# GD32M53x register map
File version: 1.0
CPU: CM33 r2p1, little endian, MPU, FPU, DSP, 4 interrupt priority bits
Registers are 32-bit, read-write, reset 0x0 unless marked. A register's access mark holds for its fields unless they carry their own. Offsets are from the block's base; [hi:lo] are bit positions; {n}, {i} and the like mark numbered series.

## CFMU — Clock frequency measurement unit
Base 0x4000C800
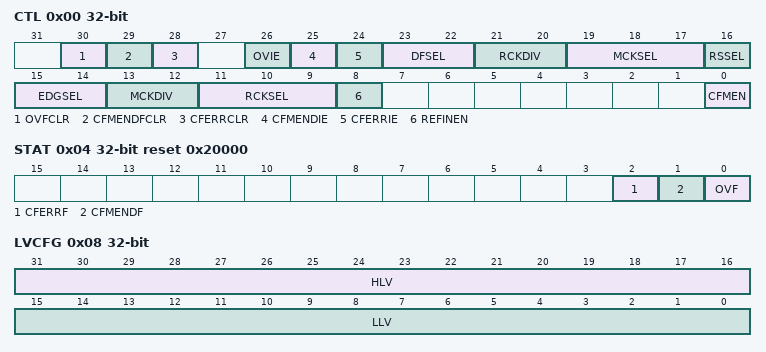
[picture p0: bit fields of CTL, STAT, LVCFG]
0x00 CTL — Control register
  [30] OVFCLR — Overflow flag clear
  [29] CFMENDFCLR — Clock frequency measurement end flag clear
  [28] CFERRCLR — Clock frequency error flag clear
  [26] OVIE — Overflow interrupt enable
  [25] CFMENDIE — Clock frequency measurement end interrupt enable
  [24] CFERRIE — Clock frequency error interrupt enable
  [23:22] DFSEL — Digital filter select
  [21:20] RCKDIV — Reference clock frequency divider
  [19:17] MCKSEL — Measurement clock select
  [16] RSSEL — Reference signal select
  [15:14] EDGSEL — Edge select
  [13:12] MCKDIV — Measurement clock frequency divider
  [11:9] RCKSEL — Reference clock select
  [8] REFINEN — CFMUREF pin input enable
  [0] CFMEN — Clock frequency measurement enable
0x04 STAT ro reset 0x20000 — Status register
  [2] CFERRF — Clock frequency error flag
  [1] CFMENDF — Clock frequency measurement end flag
  [0] OVF — Counter overflow flag
0x08 LVCFG — Limit value configuration register
  [31:16] HLV — Higher-limit value
  [15:0] LLV — Lower-limit value
0x0C CNT ro — Counter value register
  [15:0] CNT — Counter value

## CMP — Comparator
Base 0x40017C00
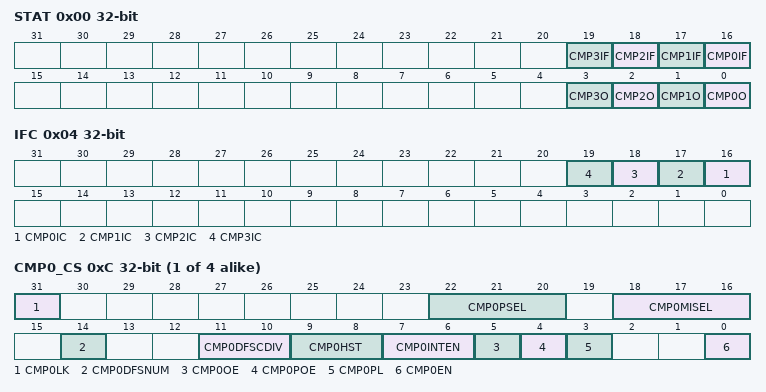
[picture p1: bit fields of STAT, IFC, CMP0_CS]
0x00 STAT ro — CMP status register
  [n+16] CMP{n}IF (n=0..3) — CMP{n} interrupt flag
  [n] CMP{n}O (n=0..3) — CMP{n} output state
0x04 IFC wo — CMP interrupt flag clear register
  [n+16] CMP{n}IC (n=0..3) — CMP{n} interrupt flag clear
{0xC+4i} CMP{i}_CS (i=0..3) — CMP{i} control and status register
  [31] CMP{i}LK — CMP{i} lock
  [22:20] CMP{i}PSEL — CMP{i}_IP input selection
  [18:16] CMP{i}MISEL — CMP{i}_IM internal input selection
  [14] CMP{i}DFSNUM — CMP{i} digital filter sampling number
  [11:10] CMP{i}DFSCDIV — CMP{i} digital filter sampling clock division
  [9:8] CMP{i}HST — CMP{i} hysteresis
  [7:6] CMP{i}INTEN — CMP{i} interrupt request enable
  [5] CMP{i}OE — CMP{i} Output Enable
  [4] CMP{i}POE — CMP{i} Pin Output Enable
  [3] CMP{i}PL — Polarity of CMP{i} output
  [0] CMP{i}EN — CMP{i} enable

## CPTIMER0
Base 0x40000000
Same registers: CPTIMER1 0x40000400
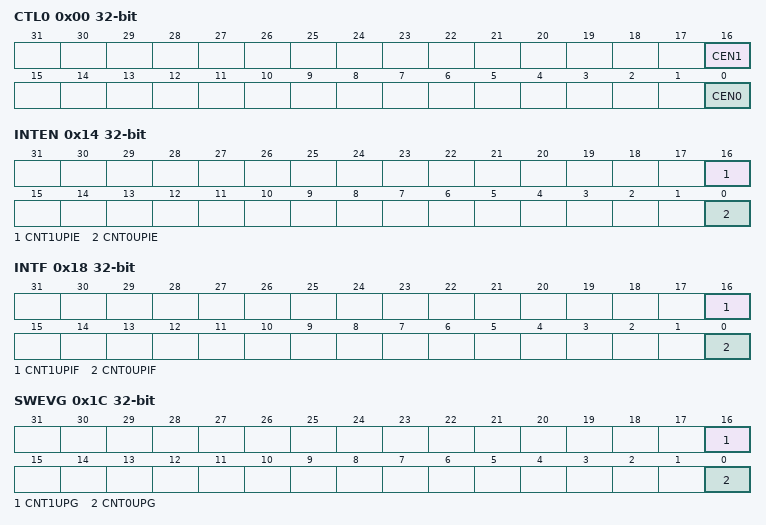
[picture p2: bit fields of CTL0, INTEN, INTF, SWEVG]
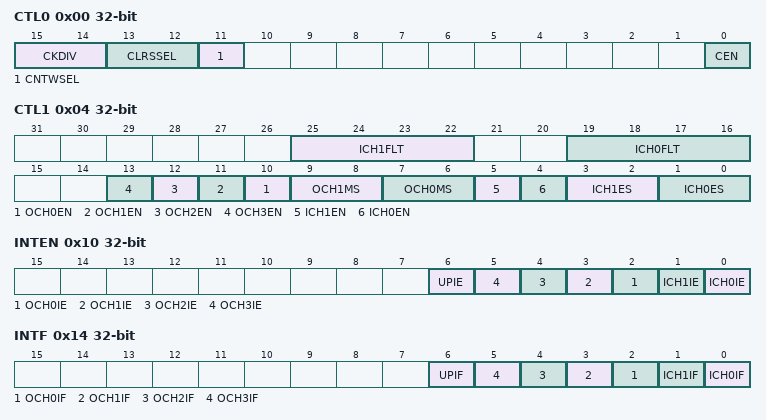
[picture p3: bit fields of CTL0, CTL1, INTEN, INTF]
0x00 CTL0 — Control register 0
  [16] CEN1 — Counter 1 enable
  [0] CEN0 — Counter 0 enable
0x04 CNT0 — Counter 0 register
  [15:0] CNT — This bit-field indicates the counter 0 current counter value. Writing to this bit-field can change the value of the counter.
0x08 CNT1 — Counter 1 register
  [15:0] CNT — This bit-field indicates the counter 1 current counter value. Writing to this bit-field can change the value of the counter.
0x0C CNT0PSC — Counter 0 prescaler register
  [15:0] CNT0PSC — Prescaler value of the counter 0 clock
0x10 CNT1PSC — Counter 1 prescaler register
  [15:0] PSC — Prescaler value of the counter 1 clock
0x14 INTEN — Interrupt enable register
  [16] CNT1UPIE — Counter 1 update interrupt enable
  [0] CNT0UPIE — Counter 0 update interrupt enable
0x18 INTF — Interrupt flag register
  [16] CNT1UPIF — Counter 1 update interrupt flag
  [0] CNT0UPIF — Counter 0 update interrupt flag
0x1C SWEVG wo — Software event generation register
  [16] CNT1UPG — Counter 1 update event generation
  [0] CNT0UPG — Counter 0 update event generation
0x20 CNT0CAR — Counter 0 auto reload register
  [15:0] CNT0CAR — Counter 0 auto reload value.
0x24 CNT1CAR — Counter 1 auto reload register
  [15:0] CNT1CAR — Counter 1 auto reload value.

## CPTIMERW
Base 0x4000E000
0x00 CTL0 — Control register 0
  [15:14] CKDIV — Input capture sample clock division
  [13:12] CLRSSEL — Counter clear source selection
  [11] CNTWSEL — Counter width selection
  [0] CEN — Counter enable
0x04 CTL1 — Control register 1
  [25:22] ICH1FLT — Input capture channel 1 filter control
  [19:16] ICH0FLT — Input capture channel 0 filter control
  [n+10] OCH{n}EN (n=0..3) — Output compare channel {n} enable
  [9:8] OCH1MS — Output compare channel 1 mode selection
  [7:6] OCH0MS — Output compare channel 0 mode selection
  [5] ICH1EN — Input capture channel 1 enable
  [4] ICH0EN — Input capture channel 0 enable
  [3:2] ICH1ES — Input capture channel 1 edge selection
  [1:0] ICH0ES — Input capture channel 0 edge selection
0x08 PSC — Prescaler register
  [15:0] PSC — Prescaler value of the counter clock
0x0C CNT — Counter register
  [31:0] CNT — This bit-field indicates the current counter value. Writing to this bit-field can change the value of the counter.
0x10 INTEN — Interrupt enable register
  [6] UPIE — Update interrupt enable
  [n+2] OCH{n}IE (n=0..3) — Output compare channel {n} interrupt enable
  [1] ICH1IE — Input capture channel 1 interrupt enable
  [0] ICH0IE — Input capture channel 0 interrupt enable
0x14 INTF — Interrupt flag register
  [6] UPIF — Update interrupt flag
  [n+2] OCH{n}IF (n=0..3) — Output compare channel {n} interrupt flag
  [1] ICH1IF — Input capture channel 1 interrupt flag
  [0] ICH0IF — Input capture channel 0 interrupt flag
0x18 SWEVG wo — Software event generation register
  [0] UPG — Update event generation
0x1C ICH0CV — Input capture channel 0 capture value register
  [31:0] ICH0CV — Input capture channel 0 capture value.
0x20 ICH1CV — Input capture channel 1 capture value register
  [31:0] ICH1CV — Input capture channel 1 capture value.
{0x24+4i} OCH{i}CV (i=0..3) — Output compare channel {i} compare value register
  [31:0] OCH{i}CV — Output compare channel {i} compare value.
0x34 CAR — Counter auto reload register
  [31:0] CAR — Counter auto reload value.
